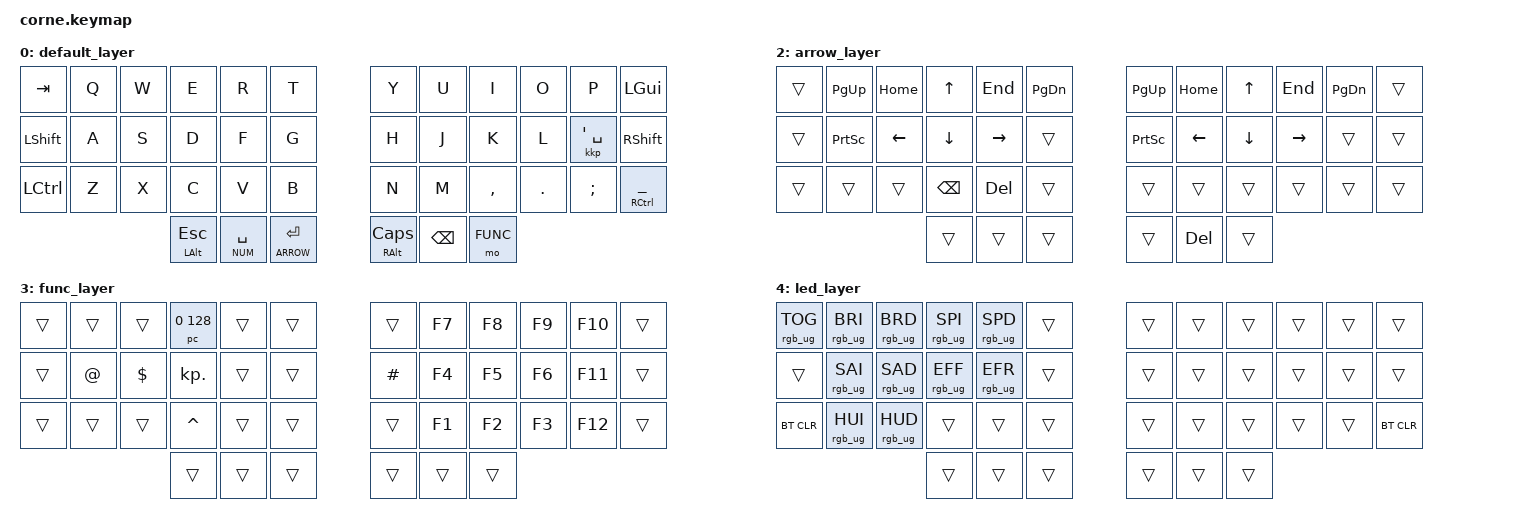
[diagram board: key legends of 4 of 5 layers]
/*
 * Copyright (c) 2020 The ZMK Contributors
 *
 * SPDX-License-Identifier: MIT
 */

#include <behaviors.dtsi>
#include <dt-bindings/zmk/keys.h>
#include <dt-bindings/zmk/bt.h>
#include <dt-bindings/zmk/rgb.h>

#define DEFAULT 0
#define NUM 1
#define ARROW 2
#define FUNC 3
#define LED 4

#define _ 10 // NOT USED: only for &pc behavior

&mt {
    flavor = "hold-preferred";
    tapping-term-ms = <150>;
    quick_tap_ms = <50>;
};

&lt {
    flavor = "hold-preferred";
    tapping-term-ms = <250>;
    quick_tap_ms = <150>;
    retro-tap;
};

/ {
    combos {
        compatible = "zmk,combos";
        combo_led {
            timeout-ms = <50>;
            key-positions = <36 37 38>;
            bindings = <&mo LED>;
        };
    };
};

/ {
        behaviors {
           am: alpha_mods {
                compatible = "zmk,behavior-hold-tap";
                label = "alpha mod-taps";
                #binding-cells = <2>;
                tapping-term-ms = <250>;
                quick-tap-ms = <150>;
                flavor = "tap-preferred";
                bindings = <&kp>, <&kp>;
                retro-tap;
            };
        };

        keymap {
                compatible = "zmk,keymap";

                default_layer {
// -----------------------------------------------------------------------------------------
// |  TAB |  Q  |  W  |  E  |  R  |  T  |   |  Y  |  U   |  I  |  O  |  P  | GUI  |
// | SHFT |  A  |  S  |  D  |  F  |  G  |   |  H  |  J   |  K  |  L  |  ;  | SHFT |
// | CTRL |  Z  |  X  |  C  |  V  |  B  |   |  N  |  M   |  ,  |  .  |  _  |  '   |
//                    | ALT | SPC | ENT |   | B/D | RSE  | AGR |
                        bindings = <
   &kp TAB   &kp Q     &kp W     &kp E     &kp R     &kp T              &kp Y     &kp U     &kp I     &kp O     &kp P          &kp LGUI
   &kp LSHFT &kp A     &kp S     &kp D     &kp F     &kp G              &kp H     &kp J     &kp K     &kp L     &kkp SQT SPACE &kp RSHFT
   &kp LCTRL &kp Z     &kp X     &kp C     &kp V     &kp B              &kp N     &kp M     &kp COMMA &kp DOT   &kp SEMI       &am RCTRL UNDER
   &mt LALT ESC        &lt NUM SPACE       &lt ARROW RET                &mt RALT CAPS            &kp BSPC                 &mo FUNC            
                        >;
                };

                num_layer {
// -----------------------------------------------------------------------------------------
// |      |     |  !  |  (  |  )  |  &  |   |  *  |  7  |  8  |  9  |  /  |  \   |
// |      |     |  ?  |  {  |  }  | "|" |   |  +  |  4  |  5  |  6  |  -  |  %   |
// |      |     |  ~  |  [  |  ]  |  ^  |   |  0  |  1  |  2  |  3  |  =  | NLCK |
//                    |     |     |     |   |     |     |     |
                        bindings = <
   &kp BSLH        &kp FSLH  &kp KP_N7 &kp KP_N8 &kp KP_N9 &kp KP_MULTIPLY                &kp AMPS         &kp LPAR &kp RPAR  &kp EXCL         &khkp RALT N1   &pc _ 166       
   &kp PRCNT       &kp MINUS &kp KP_N4 &kp KP_N5 &kp KP_N6 &kp KP_PLUS                    &kp PIPE         &kp LBRC &kp RBRC  &kp QMARK        &khkp RALT FSLH &pc _ 167        
   &am LCTRL EQUAL &kp KP_N0 &kp KP_N1 &kp KP_N2 &kp KP_N3 &kp KP_DOT                     &kkp CARET SPACE &kp LBKT &kp RBKT  &kkp TILDE SPACE &pc _ 250       &kp KP_NUM     
   &trans          &trans              &trans                                             &trans           &trans             &trans
                        >;
                };

                arrow_layer {
// -----------------------------------------------------------------------------------------
// |      |     | ←←← |  ↑  | →→→ |     |   |     |     | ←←← |  ↑  | →→→ |      |
// |      |     |  ←  |  ↓  |  →  |     |   |     |     |  ←  |  ↓  |  →  |      |
// |      |     |     |     |     |     |   |     |     |     |     |     |      |
//                    |     |     |     |   |     |     |     |
                        bindings = <
   &trans    &kp PAGE_UP &kp HOME  &kp UP    &kp END   &kp PAGE_DOWN      &kp PAGE_UP &kp HOME  &kp UP    &kp END   &kp PAGE_DOWN &trans
   &trans    &kp PSCRN   &kp LEFT  &kp DOWN  &kp RIGHT &trans             &kp PSCRN   &kp LEFT  &kp DOWN  &kp RIGHT &trans        &trans
   &trans    &trans      &trans    &kp BSPC  &kp DEL   &trans             &trans      &trans    &trans    &trans    &trans        &trans
   &trans                &trans              &trans                       &trans                &kp DEL             &trans
                        >;
                };

                func_layer {
// -----------------------------------------------------------------------------------------
// |      |  '  |     |     |     |     |   |     | F10 | F7  | F8  | F9  |      |
// |      |  @  |  $  |  .  |     |     |   |  #  | F11 | F4  | F5  | F6  |      |
// |      |     |     |  ^  |     |     |   |     | F12 | F1  | F2  | F3  |      |
//                    |     |     |     |   |     |     |     |
                        bindings = <
   &trans    &trans    &trans    &pc 0 128  &trans   &trans             &trans    &kp F7    &kp F8    &kp F9    &kp F10   &trans
   &trans    &kp AT    &kp DLLR  &kp KP_DOT &trans   &trans             &kp HASH  &kp F4    &kp F5    &kp F6    &kp F11   &trans
   &trans    &trans    &trans    &kp CARET  &trans   &trans             &trans    &kp F1    &kp F2    &kp F3    &kp F12   &trans
   &trans              &trans               &trans                      &trans              &trans              &trans
                        >;
                };

                led_layer {
// -----------------------------------------------------------------------------------------
// | ON/OFF | BRI | BRD | SPI | SPD |     |   |     |     |     |     |     |      |
// |        | SAI | SAD | EFF | EFR |     |   |     |     |     |     |     |      |
// |        | HUI | HUD |     |     |     |   |     |     |     |     |     |      |
//                      |     |     |     |   |     |     |     |
                        bindings = <
   &rgb_ug RGB_TOG     &rgb_ug RGB_BRI     &rgb_ug RGB_BRD     &rgb_ug RGB_SPI     &rgb_ug RGB_SPD     &trans                 &trans    &trans    &trans    &trans    &trans    &trans
   &trans              &rgb_ug RGB_SAI     &rgb_ug RGB_SAD     &rgb_ug RGB_EFF     &rgb_ug RGB_EFR     &trans                 &trans    &trans    &trans    &trans    &trans    &trans
   &bt BT_CLR          &rgb_ug RGB_HUI     &rgb_ug RGB_HUD     &trans              &trans              &trans                 &trans    &trans    &trans    &trans    &trans    &bt BT_CLR
                                                               &trans              &trans              &trans                 &trans              &trans              &trans
                        >;
                };
        };
};
